# M251_v1 register map
File version: 1.0
Registers are 32-bit, read-write, reset 0x0 unless marked. A register's access mark holds for its fields unless they carry their own. Offsets are from the block's base; [hi:lo] are bit positions; {n}, {i} and the like mark numbered series; 'fields as' and 'values as' point back to an identical list.

## SYS — SYS Register Map
Base 0x40000000
0x00 SYS_PDID ro reset not defined — Part Device Identification Number Register
  [31:0] PDID — Part Device Identification Number (Read Only). This register reflects device part number code. Software can read this register to identify which device is used.
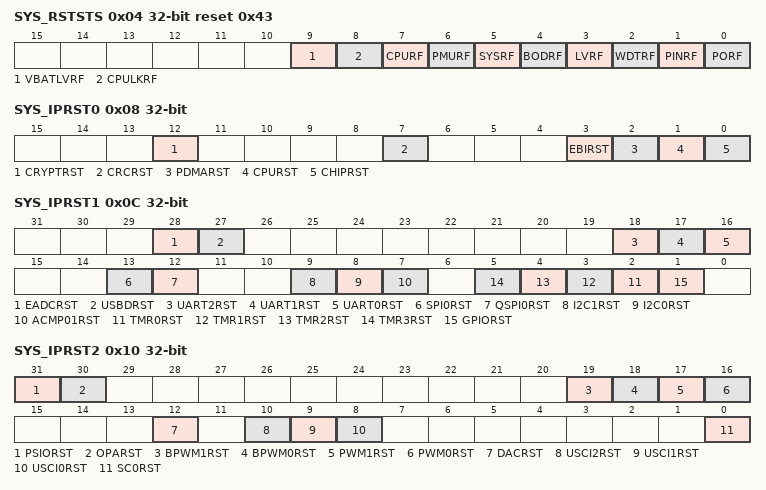
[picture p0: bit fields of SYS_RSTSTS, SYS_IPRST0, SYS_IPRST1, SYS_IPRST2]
0x04 SYS_RSTSTS reset 0x43 — System Reset Status Register
  [9] VBATLVRF — VBAT LVR Reset Flag. The VBAT LVR reset flag is set by the 'Reset Signal' from the VBAT Low Voltage Reset Controller to indicate the previous reset source. Note: Write 1 to clear this bit to 0.
    0=No reset from VBAT LVR; 1=VBAT LVR controller had issued the reset signal to reset the system
  [8] CPULKRF — CPU Lockup Reset Flag. Note: Write 1 to clear this bit to 0. Note2: When CPU lockup happened under ICE is connected, This flag will set to 1 but chip will not reset.
    0=No reset from CPU lockup happened; 1=The Cortex-M23lockup happened and chip is reset
  [7] CPURF — CPU Reset Flag. The CPU reset flag is set by hardware if software writes CPURST (SYS_IPRST0[1]) 1 to reset Cortex- M23Core and Flash Memory Controller (FMC). Note: Write 1 to clear this bit to 0.
    0=No reset from CPU; 1=The Cortex-M23 Core and FMC are reset by software setting CPURST to 1
  [6] PMURF — PMU Reset Flag, The PMU reset flag is set by any reset signal when MCU is in power down state. Note: Write 1 to clear this bit to 0.
    0=No reset in power down state; 1=Any reset signal happens in power down state
  [5] SYSRF — System Reset Flag. The system reset flag is set by the 'Reset Signal' from the CortexM23Core to indicate the previous reset source. Note: Write 1 to clear this bit to 0.
    0=No reset from Cortex-M23; 1=The Cortex- M23 had issued the reset signal to reset the system by writing 1 to the bit SYSRESETREQ(AIRCR[2], Application Interrupt and Reset Control Register, address = 0xE000ED0C) in system control registers of Cortex-M23core
  [4] BODRF — BOD Reset Flag. The BOD reset flag is set by the 'Reset Signal' from the Brown-Out Detector to indicate the previous reset source. Note: Write 1 to clear this bit to 0.
    0=No reset from BOD; 1=The BOD had issued the reset signal to reset the system
  [3] LVRF — LVR Reset Flag. The LVR reset flag is set by the 'Reset Signal' from the Low Voltage Reset Controller to indicate the previous reset source. Note: Write 1 to clear this bit to 0.
    0=No reset from LVR; 1=LVR controller had issued the reset signal to reset the system
  [2] WDTRF — WDT Reset Flag. The WDT reset flag is set by the 'Reset Signal' from the Watchdog Timer or Window Watchdog Timer to indicate the previous reset source. Note1: Write 1 to clear this bit to 0. Note2: Watchdog Timer register RSTF(WDT_CTL[2]) bit is set if the system has been reset by WDT time-out reset. Window Watchdog Timer register WWDTRF(WWDT_STATUS[1]) bit is set if the system has been reset by WWDT time-out reset.
    0=No reset from watchdog timer or window watchdog timer; 1=The watchdog timer or window watchdog timer had issued the reset signal to reset the system
  [1] PINRF — NRESET Pin Reset Flag. The nRESET pin reset flag is set by the 'Reset Signal' from the nRESET Pin to indicate the previous reset source. Note: Write 1 to clear this bit to 0.
    0=No reset from nRESET pin; 1=Pin nRESET had issued the reset signal to reset the system
  [0] PORF — POR Reset Flag. The POR reset flag is set by the 'Reset Signal' from the Power-on Reset (POR) Controller or bit CHIPRST (SYS_IPRST0[0]) to indicate the previous reset source. Note: Write 1 to clear this bit to 0.
    0=No reset from POR or CHIPRST; 1=Power-on Reset (POR) or CHIPRST had issued the reset signal to reset the system
0x08 SYS_IPRST0 — Peripheral Reset Control Register 0
  [12] CRYPTRST — CRYPTO Controller Reset (Write Protect). Setting this bit to 1 will generate a reset signal to the CRYPTO controller. User needs to set this bit to 0 to release from the reset state. Note: This bit is write protected. Refer to the SYS_REGLCTL register.
    0=CRYPTO controller normal operation; 1=CRYPTO controller reset
  [7] CRCRST — CRC Calculation Controller Reset (Write Protect). Setting this bit to 1 will generate a reset signal to the CRC calculation controller. User needs to set this bit to 0 to release from the reset state. Note: This bit is write protected. Refer to the SYS_REGLCTL register.
    0=CRC calculation controller normal operation; 1=CRC calculation controller reset
  [3] EBIRST — EBI Controller Reset (Write Protect). Setting this bit to 1 will generate a reset signal to the EBI. User needs to set this bit to 0 to release from the reset state. Note: This bit is write protected. Refer to the SYS_REGLCTL register.
    0=EBI controller normal operation; 1=EBI controller reset
  [2] PDMARST — PDMA Controller Reset (Write Protect). Setting this bit to 1 will generate a reset signal to the PDMA. User needs to set this bit to 0 to release from reset state. Note: This bit is write protected. Refer to the SYS_REGLCTL register.
    0=PDMA controller normal operation; 1=PDMA controller reset
  [1] CPURST — Processor Core One-shot Reset (Write Protect). Setting this bit will only reset the processor core and Flash Memory Controller(FMC), and this bit will automatically return to 0 after the 2 clock cycles. Note: This bit is write protected. Refer to the SYS_REGLCTL register.
    0=Processor core normal operation; 1=Processor core one-shot reset
  [0] CHIPRST — Chip One-shot Reset (Write Protect). Setting this bit will reset the whole chip, including Processor core and all peripherals, and this bit will automatically return to 0 after the 2 clock cycles. The CHIPRST is same as the POR reset, all the chip controllers is reset and the chip setting from Flash are also reload. For the difference between CHIPRST and SYSRESETREQ(AIRCR[2]), please refer to section 6.2.2. Note1: This bit is write protected. Refer to the SYS_REGLCTL register. Note2: Reset by power on reset
    0=Chip normal operation; 1=Chip one-shot reset
0x0C SYS_IPRST1 — Peripheral Reset Control Register 1
  [28] EADCRST — EADC Controller Reset
    0=EADC controller normal operation; 1=EADC controller reset
  [27] USBDRST — USBD Controller Reset
    0=USBD controller normal operation; 1=USBD controller reset
  [18] UART2RST — UART2 Controller Reset
    0=UART2 controller normal operation; 1=UART2 controller reset
  [17] UART1RST — UART1 Controller Reset
    0=UART1 controller normal operation; 1=UART1 controller reset
  [16] UART0RST — UART0 Controller Reset
    0=UART0 controller normal operation; 1=UART0 controller reset
  [13] SPI0RST — SPI0 Controller Reset
    0=SPI0 controller normal operation; 1=SPI0 controller reset
  [12] QSPI0RST — QSPI0 Controller Reset
    0=QSPI0 controller normal operation; 1=QSPI0 controller reset
  [9] I2C1RST — I2C1 Controller Reset
    0=I2C1 controller normal operation; 1=I2C1 controller reset
  [8] I2C0RST — I2C0 Controller Reset
    0=I2C0 controller normal operation; 1=I2C0 controller reset
  [7] ACMP01RST — Analog Comparator 0/1 Controller Reset
    0=Analog Comparator 0/1 controller normal operation; 1=Analog Comparator 0/1 controller reset
  [n+2] TMR{n}RST (n=0..3) — Timer{n} Controller Reset
    0=Timer{n} controller normal operation; 1=Timer{n} controller reset
  [1] GPIORST — GPIO Controller Reset
    0=GPIO controller normal operation; 1=GPIO controller reset
0x10 SYS_IPRST2 — Peripheral Reset Control Register 2
  [31] PSIORST
  [30] OPARST — OP Amplifier (OPA) Controller Reset
    0=OPA controller normal operation; 1=OPA controller reset
  [19] BPWM1RST — BPWM1 Controller Reset
    0=BPWM1 controller normal operation; 1=BPWM1 controller reset
  [18] BPWM0RST — BPWM0 Controller Reset
    0=BPWM0 controller normal operation; 1=BPWM0 controller reset
  [17] PWM1RST — PWM1 Controller Reset
    0=PWM1 controller normal operation; 1=PWM1 controller reset
  [16] PWM0RST — PWM0 Controller Reset
    0=PWM0 controller normal operation; 1=PWM0 controller reset
  [12] DACRST — DAC Controller Reset
    0=DAC controller normal operation; 1=DAC controller reset
  [10] USCI2RST — USCI2 Controller Reset
    0=USCI2 controller normal operation; 1=USCI2 controller reset
  [9] USCI1RST — USCI1 Controller Reset
    0=USCI1 controller normal operation; 1=USCI1 controller reset
  [8] USCI0RST — USCI0 Controller Reset
    0=USCI0 controller normal operation; 1=USCI0 controller reset
  [0] SC0RST — SC0 Controller Reset
    0=SC0 controller normal operation; 1=SC0 controller reset
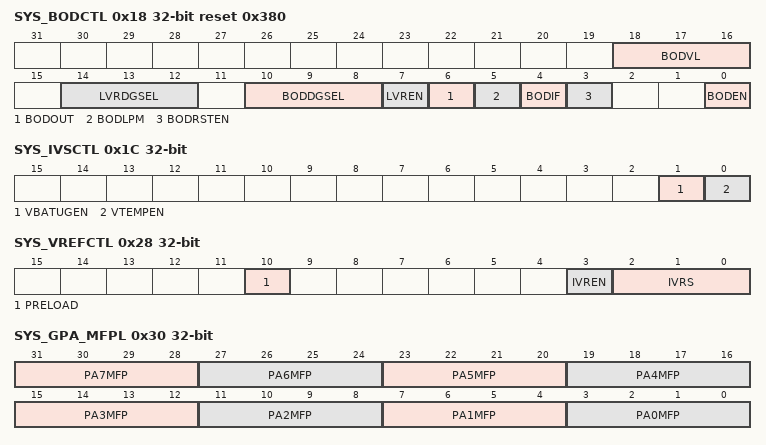
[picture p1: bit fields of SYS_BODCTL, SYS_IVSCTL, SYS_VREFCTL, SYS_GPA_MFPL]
0x18 SYS_BODCTL reset 0x380 (reset mask 0xFFF0FFF0) — Brown-out Detector Control Register
  [18:16] BODVL — Brown-out Detector Threshold Voltage Selection (Write Protect). The default value is set by Flash controller user configuration register CBOV (CONFIG0 [23:21]). Note: This bit is write protected. Refer to the SYS_REGLCTL register. Note: Reset by power on reset.
    1=Brown-Out Detector threshold voltage is 1.8V; 2=Brown-Out Detector threshold voltage is 2.0V; 3=Brown-Out Detector threshold voltage is 2.4V; 4=Brown-Out Detector threshold voltage is 2.7V; 5=Brown-Out Detector threshold voltage is 3.0V; 6=Brown-Out Detector threshold voltage is 3.7V; 7=Brown-Out Detector threshold voltage is 4.4V
  [14:12] LVRDGSEL — LVR Output De-glitch Time Select (Write Protect). Note: These bits are write protected. Refer to the SYS_REGLCTL register. Note: The MIRC enabled automatically when LVRDGSEL is not 000 and LVREN is 1.
    0=Without de-glitch function; 1=4 MIRC clock (4 MHz), 1 us; 2=8 MIRC clock (4 MHz), 2 us; 3=16 MIRC clock (4 MHz), 4 us; 4=32 MIRC clock (4 MHz), 8 us; 5=64 MIRC clock (4 MHz), 16 us; 6=128 MIRC clock (4 MHz), 32 us; 7=256 MIRC clock (4 MHz), 64 us
  [10:8] BODDGSEL — Brown-out Detector Output De-glitch Time Select (Write Protect). Note: These bits are write protected. Refer to the SYS_REGLCTL register.
    0=BOD output is sampled by LIRC; 1=4 system clock (HCLK); 2=8 system clock (HCLK); 3=16 system clock (HCLK); 4=32 system clock (HCLK); 5=64 system clock (HCLK); 6=128 system clock (HCLK); 7=256 system clock (HCLK)
  [7] LVREN — Low Voltage Reset Enable Bit (Write Protect). The LVR function resets the chip when the input power voltage is lower than LVR circuit setting. LVR function is enabled by default. Note1: After enabling the bit, the LVR function will be active with 3ms delay for LVR output stable (default). Note2: For BOD low power mode to be active, this bit must be set 1. Note3: This bit is write protected. Refer to the SYS_REGLCTL register.
    0=Low Voltage Reset function Disabled; 1=Low Voltage Reset function Enabled
  [6] BODOUT — Brown-out Detector Output Status. It means the detected voltage is lower than BODVL setting. If the BODEN is 0, BOD function disabled, this bit always responds 0000.
    0=Brown-out Detector output status is 0; 1=Brown-out Detector output status is 1
  [5] BODLPM — Brown-out Detector Low Power Mode (Write Protect). Note1: The BOD consumes about 100uA in normal mode, the low power mode can reduce the current to about 1/10 but slow the BOD response. Note2: For BOD low power mode to be active, LVREN must be set to 1. Note3: This bit is write protected. Refer to the SYS_REGLCTL register.
    0=BOD operate in normal mode (default); 1=BOD Low Power mode Enabled
  [4] BODIF — Brown-out Detector Interrupt Flag. Note: Write 1 to clear this bit to 0.
    0=Brown-out Detector does not detect any voltage draft at VDD down through or up through the voltage of BODVL setting; 1=When Brown-out Detector detects the VDD is dropped down through the voltage of BODVL setting or the VDD is raised up through the voltage of BODVL setting, this bit is set to 1 and the brown-out interrupt is requested if brown-out interrupt is enabled
  [3] BODRSTEN — Brown-out Reset Enable Bit (Write Protect). The default value is set by Flash controller user configuration register CBORST(CONFIG0[20]) bit. Note1: While the Brown-out Detector function is enabled (BODEN high) and BOD reset function is enabled (BODRSTEN high), BOD will assert a signal to reset chip when the detected voltage is lower than the threshold (BODOUT high). While the BOD function is enabled (BODEN high) and BOD interrupt function is enabled (BODRSTEN low), BOD will assert an interrupt if BODOUT is high. BOD interrupt will keep till to the BODEN set to 0. BOD interrupt can be blocked by disabling the NVIC BOD interrupt or disabling BOD function (set BODEN low). Note2: This bit is write protected. Refer to the SYS_REGLCTL register. Note3: Reset by power on reset.
    0=Brown-out 'INTERRUPT' function Enabled; 1=Brown-out 'RESET' function Enabled
  [0] BODEN — Brown-out Detector Enable Bit (Write Protect). The default value is set by Flash controller user configuration register CBODEN (CONFIG0 [19]). Note1: This bit is write protected. Refer to the SYS_REGLCTL register. Note2: Reset by power on reset.
    0=Brown-out Detector function Disabled; 1=Brown-out Detector function Enabled
0x1C SYS_IVSCTL — Internal Voltage Source Control Register
  [1] VBATUGEN — VBAT Unity Gain Buffer Enable Bit. This bit is used to enable/disable VBAT unity gain buffer function. Note: After this bit is set to 1, the value of VBAT unity gain buffer output voltage can be obtained from ADC conversion result
    0=VBAT unity gain buffer function Disabled (default); 1=VBAT unity gain buffer function Enabled
  [0] VTEMPEN — Temperature Sensor Enable Bit. This bit is used to enable/disable temperature sensor function. .
    0=Temperature sensor function Disabled (default); 1=Temperature sensor function Enabled
0x24 SYS_PORCTL0 — Power-On-reset Controller Register 0
  [15:0] PORMASK — Power-on Reset Mask Enable Bit (Write Protect). When powered on, the POR circuit generates a reset signal to reset the whole chip function, but noise on the power may cause the POR active again. User can mask internal POR signal to avoid unpredictable noise to cause chip reset by writing 0x5AA5 to this field. The POR function will be active again when this field is set to another value or chip is reset by other reset source, including: nRESET, Watchdog, LVR reset, BOD reset, ICE reset command and the software-chip reset function. Note: These bits are write protected. Refer to the SYS_REGLCTL register.
0x28 SYS_VREFCTL — VREF Control Register
  [10] PRELOAD — Preload Enable Bit. Note: This bit is used to speed up charging external capacitor of VREF.If INT_VREF voltage is stable, this bit has to be disabled.
    0=Preload Disabled (default); 1=Preload Enabled
  [3] IVREN — Internal Voltage Reference Module Enable Bit (Write Protect)
    0=Internal voltage reference module Disabled; 1=Internal voltage reference module Enabled
  [2:0] IVRS — Internal Voltage Reference Scale (Write Protect)
    0=Internal voltage reference(INT_VREF) set to 1.536V; 1=Internal voltage reference(INT_VREF) set to 2.048V; 2=Internal voltage reference(INT_VREF) set to 2.56V; 3=Internal voltage reference(INT_VREF) set to 3.072V; 4=Internal voltage reference(INT_VREF) set to 4.096V
0x30 SYS_GPA_MFPL — GPIOA Low Byte Multiple Function Control Register
  [31:28] PA7MFP — PA.7 Multi-function Pin Selection
  [27:24] PA6MFP — PA.6 Multi-function Pin Selection
  [23:20] PA5MFP — PA.5 Multi-function Pin Selection
  [19:16] PA4MFP — PA.4 Multi-function Pin Selection
  [15:12] PA3MFP — PA.3 Multi-function Pin Selection
  [11:8] PA2MFP — PA.2 Multi-function Pin Selection
  [7:4] PA1MFP — PA.1 Multi-function Pin Selection
  [3:0] PA0MFP — PA.0 Multi-function Pin Selection
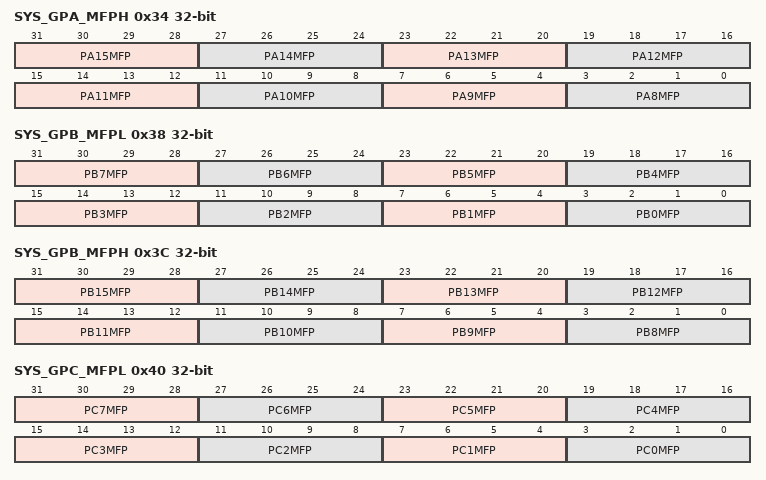
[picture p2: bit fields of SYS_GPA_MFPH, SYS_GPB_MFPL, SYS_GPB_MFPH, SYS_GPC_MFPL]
0x34 SYS_GPA_MFPH — GPIOA High Byte Multiple Function Control Register
  [31:28] PA15MFP — PA.15 Multi-function Pin Selection
  [27:24] PA14MFP — PA.14 Multi-function Pin Selection
  [23:20] PA13MFP — PA.13 Multi-function Pin Selection
  [19:16] PA12MFP — PA.12 Multi-function Pin Selection
  [15:12] PA11MFP — PA.11 Multi-function Pin Selection
  [11:8] PA10MFP — PA.10 Multi-function Pin Selection
  [7:4] PA9MFP — PA.9 Multi-function Pin Selection
  [3:0] PA8MFP — PA.8 Multi-function Pin Selection
0x38 SYS_GPB_MFPL — GPIOB Low Byte Multiple Function Control Register
  [31:28] PB7MFP — PB.7 Multi-function Pin Selection
  [27:24] PB6MFP — PB.6 Multi-function Pin Selection
  [23:20] PB5MFP — PB.5 Multi-function Pin Selection
  [19:16] PB4MFP — PB.4 Multi-function Pin Selection
  [15:12] PB3MFP — PB.3 Multi-function Pin Selection
  [11:8] PB2MFP — PB.2 Multi-function Pin Selection
  [7:4] PB1MFP — PB.1 Multi-function Pin Selection
  [3:0] PB0MFP — PB.0 Multi-function Pin Selection
0x3C SYS_GPB_MFPH — GPIOB High Byte Multiple Function Control Register
  [31:28] PB15MFP — PB.15 Multi-function Pin Selection
  [27:24] PB14MFP — PB.14 Multi-function Pin Selection
  [23:20] PB13MFP — PB.13 Multi-function Pin Selection
  [19:16] PB12MFP — PB.12 Multi-function Pin Selection
  [15:12] PB11MFP — PB.11 Multi-function Pin Selection
  [11:8] PB10MFP — PB.10 Multi-function Pin Selection
  [7:4] PB9MFP — PB.9 Multi-function Pin Selection
  [3:0] PB8MFP — PB.8 Multi-function Pin Selection
0x40 SYS_GPC_MFPL — GPIOC Low Byte Multiple Function Control Register
  [31:28] PC7MFP — PC.7 Multi-function Pin Selection
  [27:24] PC6MFP — PC.6 Multi-function Pin Selection
  [23:20] PC5MFP — PC.5 Multi-function Pin Selection
  [19:16] PC4MFP — PC.4 Multi-function Pin Selection
  [15:12] PC3MFP — PC.3 Multi-function Pin Selection
  [11:8] PC2MFP — PC.2 Multi-function Pin Selection
  [7:4] PC1MFP — PC.1 Multi-function Pin Selection
  [3:0] PC0MFP — PC.0 Multi-function Pin Selection
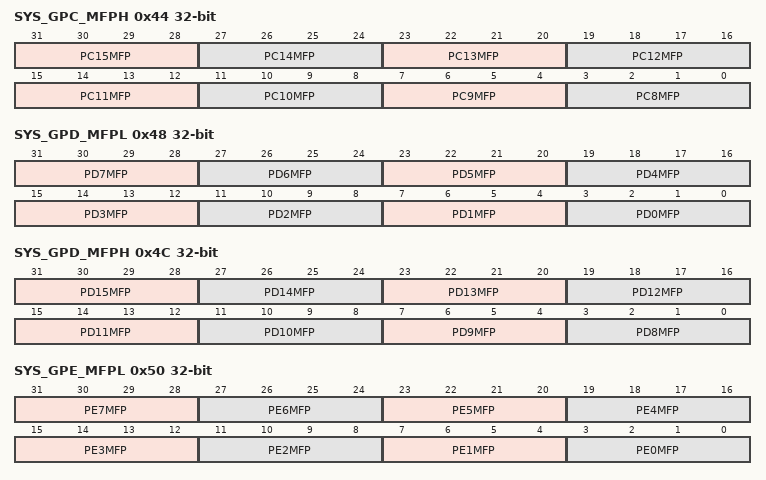
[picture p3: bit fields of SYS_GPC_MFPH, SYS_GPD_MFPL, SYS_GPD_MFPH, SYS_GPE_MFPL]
0x44 SYS_GPC_MFPH — GPIOC High Byte Multiple Function Control Register
  [31:28] PC15MFP — PC.15 Multi-function Pin Selection
  [27:24] PC14MFP — PC.14 Multi-function Pin Selection
  [23:20] PC13MFP — PC.13 Multi-function Pin Selection
  [19:16] PC12MFP — PC.12 Multi-function Pin Selection
  [15:12] PC11MFP — PC.11 Multi-function Pin Selection
  [11:8] PC10MFP — PC.10 Multi-function Pin Selection
  [7:4] PC9MFP — PC.9 Multi-function Pin Selection
  [3:0] PC8MFP — PC.8 Multi-function Pin Selection
0x48 SYS_GPD_MFPL — GPIOD Low Byte Multiple Function Control Register
  [31:28] PD7MFP — PD.7 Multi-function Pin Selection
  [27:24] PD6MFP — PD.6 Multi-function Pin Selection
  [23:20] PD5MFP — PD.5 Multi-function Pin Selection
  [19:16] PD4MFP — PD.4 Multi-function Pin Selection
  [15:12] PD3MFP — PD.3 Multi-function Pin Selection
  [11:8] PD2MFP — PD.2 Multi-function Pin Selection
  [7:4] PD1MFP — PD.1 Multi-function Pin Selection
  [3:0] PD0MFP — PD.0 Multi-function Pin Selection
0x4C SYS_GPD_MFPH — GPIOD High Byte Multiple Function Control Register
  [31:28] PD15MFP — PD.15 Multi-function Pin Selection
  [27:24] PD14MFP — PD.14 Multi-function Pin Selection
  [23:20] PD13MFP — PD.13 Multi-function Pin Selection
  [19:16] PD12MFP — PD.12 Multi-function Pin Selection
  [15:12] PD11MFP — PD.11 Multi-function Pin Selection
  [11:8] PD10MFP — PD.10 Multi-function Pin Selection
  [7:4] PD9MFP — PD.9 Multi-function Pin Selection
  [3:0] PD8MFP — PD.8 Multi-function Pin Selection
0x50 SYS_GPE_MFPL — GPIOE Low Byte Multiple Function Control Register
  [31:28] PE7MFP — PE.7 Multi-function Pin Selection
  [27:24] PE6MFP — PE.6 Multi-function Pin Selection
  [23:20] PE5MFP — PE.5 Multi-function Pin Selection
  [19:16] PE4MFP — PE.4 Multi-function Pin Selection
  [15:12] PE3MFP — PE.3 Multi-function Pin Selection
  [11:8] PE2MFP — PE.2 Multi-function Pin Selection
  [7:4] PE1MFP — PE.1 Multi-function Pin Selection
  [3:0] PE0MFP — PE.0 Multi-function Pin Selection
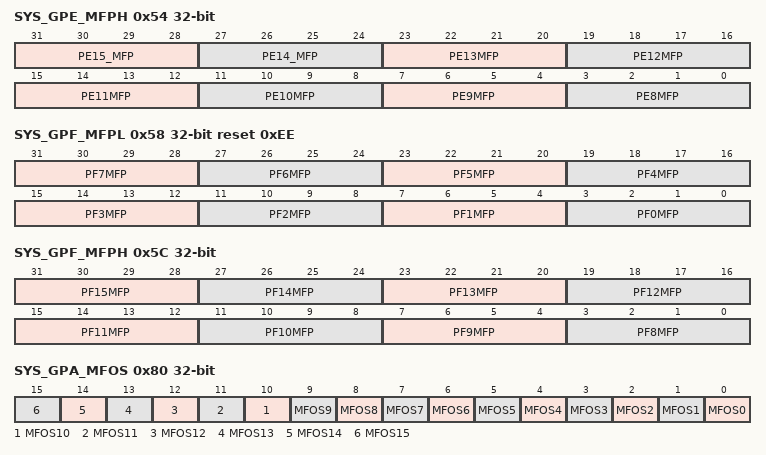
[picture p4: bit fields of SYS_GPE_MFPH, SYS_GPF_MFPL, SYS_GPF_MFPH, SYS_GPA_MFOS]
0x54 SYS_GPE_MFPH — GPIOE High Byte Multiple Function Control Register
  [31:28] PE15_MFP — PE.15 Multi-function Pin Selection
  [27:24] PE14_MFP — PE.14 Multi-function Pin Selection
  [23:20] PE13MFP — PE.13 Multi-function Pin Selection
  [19:16] PE12MFP — PE.12 Multi-function Pin Selection
  [15:12] PE11MFP — PE.11 Multi-function Pin Selection
  [11:8] PE10MFP — PE.10 Multi-function Pin Selection
  [7:4] PE9MFP — PE.9 Multi-function Pin Selection
  [3:0] PE8MFP — PE.8 Multi-function Pin Selection
0x58 SYS_GPF_MFPL reset 0xEE — GPIOF Low Byte Multiple Function Control Register
  [31:28] PF7MFP — PF.7 Multi-function Pin Selection
  [27:24] PF6MFP — PF.6 Multi-function Pin Selection
  [23:20] PF5MFP — PF.5 Multi-function Pin Selection
  [19:16] PF4MFP — PF.4 Multi-function Pin Selection
  [15:12] PF3MFP — PF.3 Multi-function Pin Selection
  [11:8] PF2MFP — PF.2 Multi-function Pin Selection
  [7:4] PF1MFP — PF.1 Multi-function Pin Selection
  [3:0] PF0MFP — PF.0 Multi-function Pin Selection
0x5C SYS_GPF_MFPH — GPIOF High Byte Multiple Function Control Register
  [31:28] PF15MFP — PF.15 Multi-function Pin Selection
  [27:24] PF14MFP — PF.14 Multi-function Pin Selection
  [23:20] PF13MFP — PF.13 Multi-function Pin Selection
  [19:16] PF12MFP — PF.12 Multi-function Pin Selection
  [15:12] PF11MFP — PF.11 Multi-function Pin Selection
  [11:8] PF10MFP — PF.10 Multi-function Pin Selection
  [7:4] PF9MFP — PF.9 Multi-function Pin Selection
  [3:0] PF8MFP — PF.8 Multi-function Pin Selection
0x80 SYS_GPA_MFOS — GPIOA Multiple Function Output Select Register
  [all] fields
    0=Multiple funtion pin output mode type is Push-pull mode; 1=Multiple funtion pin output mode type is Open-drain mode
  [n] MFOS{n} (n=0..15) — GPIOA-f Pin[n] Multiple Function Pin Output Mode Select. This bit used to select multiple function pin output mode type for Px.n pin
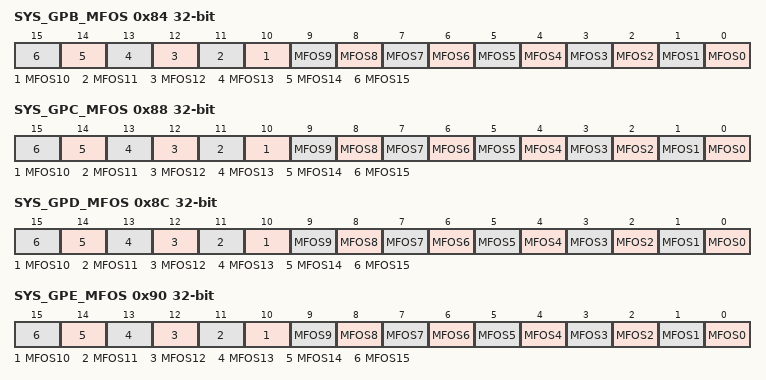
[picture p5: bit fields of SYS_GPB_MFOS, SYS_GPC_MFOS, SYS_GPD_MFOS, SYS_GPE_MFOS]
0x84 SYS_GPB_MFOS — GPIOB Multiple Function Output Select Register
  fields as SYS_GPA_MFOS
0x88 SYS_GPC_MFOS — GPIOC Multiple Function Output Select Register
  fields as SYS_GPA_MFOS
0x8C SYS_GPD_MFOS — GPIOD Multiple Function Output Select Register
  fields as SYS_GPA_MFOS
0x90 SYS_GPE_MFOS — GPIOE Multiple Function Output Select Register
  fields as SYS_GPA_MFOS
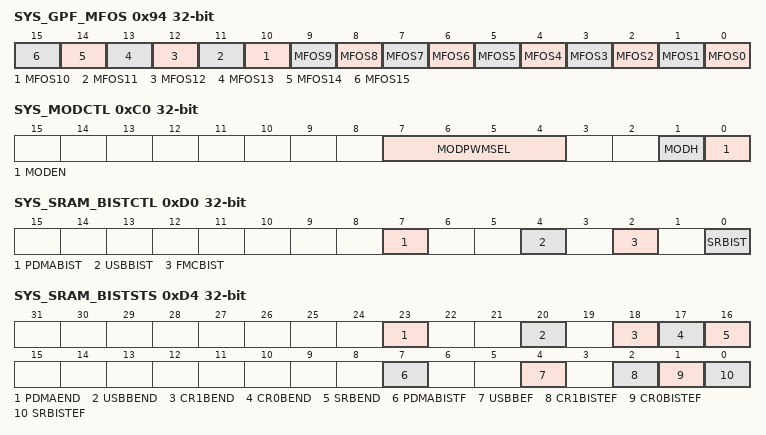
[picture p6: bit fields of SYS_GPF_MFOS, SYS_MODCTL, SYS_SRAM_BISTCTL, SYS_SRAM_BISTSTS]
0x94 SYS_GPF_MFOS — GPIOF Multiple Function Output Select Register
  fields as SYS_GPA_MFOS
0xC0 SYS_MODCTL — Modulation Control Register
  [7:4] MODPWMSEL — PWM0 Channel Select for Modulation. Select the PWM0 channel to modulate with the UART0_TXD or USCI0_DAT1. 0000: PWM0 Channel 0 modulate with UART0_TXD. 0001: PWM0 Channel 1 modulate with UART0_TXD. 0010: PWM0 Channel 2 modulate with UART0_TXD. 0011: PWM0 Channel 3 modulete with UART0_TXD. 0100: PWM0 Channel 4 modulete with UART0_TXD. 0101: PWM0 Channel 5 modulete with UART0_TXD. 0110: Reserved. 0111: Reserved. 1000: PWM0 Channel 0 modulate with USCI0_DAT1. 1001: PWM0 Channel 1 modulate with USCI0_DAT1. 1010: PWM0 Channel 2 modulate with USCI0_DAT1. 1011: PWM0 Channel 3 modulete with USCI0_DAT1. 1100: PWM0 Channel 4 modulete with USCI0_DAT1. 1101: PWM0 Channel 5 modulete with USCI0_DAT1. 1110: Reserved. 1111: Reserved. Note: This bis is valid while MODEN (SYS_MODCTL[0]) is set to 1.
  [1] MODH — Modulation at Data High. Select modulation pulse(PWM0) at high or low of UART0_TXD or USCI0_DAT1
    0=Modulation pulse at UART0_TXD low or USCI0_DAT1 low; 1=Modulation pulse at UART0_TXD high or USCI0_DAT1 high
  [0] MODEN — Modulation Function Enable Bit. This bit enables modulation funcion by modulating with PWM0 channel output and USCI0(USCI0_DAT1) or UART0(UART0_TXD) output.
    0=Modulation Function Disabled; 1=Modulation Function Enabled
0xD0 SYS_SRAM_BISTCTL — System SRAM BIST Test Control Register
  [7] PDMABIST — PDMA BIST Enable Bit (Write Protect). This bit enables BIST test for PDMA RAM. Note: This bit is write protected. Refer to the SYS_REGLCTL register.
    0=System PDMA BIST Disabled; 1=Sstem PDMA BIST Enabled
  [4] USBBIST — USB BIST Enable Bit (Write Protect). This bit enables BIST test for USB RAM. Note: This bit is write protected. Refer to the SYS_REGLCTL register.
    0=System USB BIST Disabled; 1=System USB BIST Enabled
  [2] FMCBIST — FMC CACHE BIST Enable Bit (Write Protect). This bit enables BIST test for CACHE RAM. Note: This bit is write protected. Refer to the SYS_REGLCTL register.
    0=System CACHE BIST Disabled; 1=System CACHE BIST Enabled
  [0] SRBIST — SRAM BIST Enable Bit (Write Protect). This bit enables BIST test for SRAM. Note: This bit is write protected. Refer to the SYS_REGLCTL register.
    0=System SRAM BIST Disabled; 1=System SRAM BIST Enabled
0xD4 SYS_SRAM_BISTSTS ro (reset mask 0xFF00FF00) — System SRAM BIST Test Status Register
  [23] PDMAEND — PDMA SRAM BIST Test Finish
    0=PDMA SRAM BIST is active; 1=PDMA SRAM BIST test finished
  [20] USBBEND — USB SRAM BIST Test Finish
    0=USB SRAM BIST is active; 1=USB SRAM BIST test finished
  [18] CR1BEND — CACHE 1 SRAM BIST Test Finish
    0=System CACHE RAM BIST is active; 1=System CACHE RAM BIST test finished
  [17] CR0BEND — CACHE 0 SRAM BIST Test Finish
    values as CR1BEND
  [16] SRBEND — SRAM BIST Test Finish
    0=System SRAM BIST active; 1=system SRAM BIST finished
  [7] PDMABISTF — PDMA SRAM BIST Failed Flag
    0=PDMA SRAM BIST pass; 1=PDMA SRAM BIST failed
  [4] USBBEF — USB SRAM BIST Fail Flag
    0=USB SRAM BIST test pass; 1=USB SRAM BIST test failed
  [2] CR1BISTEF — CACHE1 SRAM BIST Fail Flag
    0=System CACHE RAM BIST test pass; 1=System CACHE RAM BIST test failed
  [1] CR0BISTEF — CACHE0 SRAM BIST Fail Flag
    values as CR1BISTEF
  [0] SRBISTEF — System SRAM BIST Fail Flag
    0=System SRAM BIST test pass; 1=System SRAM BIST test failed
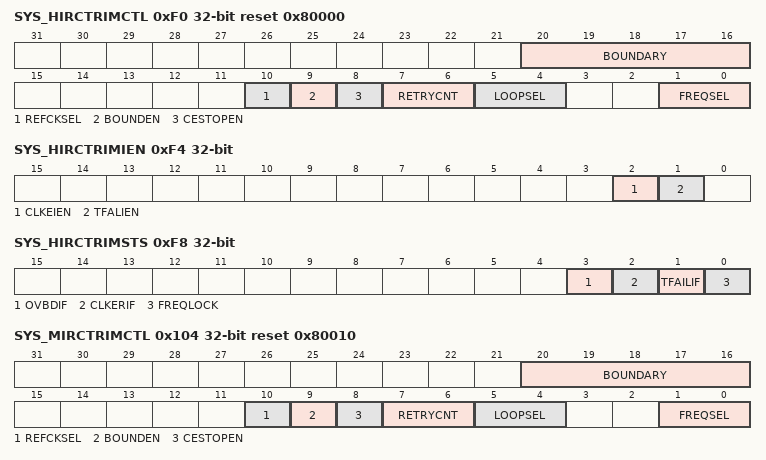
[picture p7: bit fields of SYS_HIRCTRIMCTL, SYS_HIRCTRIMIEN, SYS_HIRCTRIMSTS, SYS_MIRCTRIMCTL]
0xF0 SYS_HIRCTRIMCTL reset 0x80000 — HIRC Trim Control Register
  [20:16] BOUNDARY — Boundary Selection. Fill the boundary range from 0x1 to 0x1F, 0x0 is reserved. Note: This field is effective only when the BOUNDEN(SYS_HIRCTRIMCTL[9]) is enable.
  [10] REFCKSEL — Reference Clock Selection
    0=HIRC trim reference clock is from LXT (32.768 kHz); 1=HIRC trim reference clock is from internal USB synchronous mode
  [9] BOUNDEN — Boundary Enable Bit
    0=Boundary function Disabled; 1=Boundary function Enabled
  [8] CESTOPEN — Clock Error Stop Enable Bit
    0=The trim operation keeps going if clock is inaccurate; 1=The trim operation stops if clock is inaccurate
  [7:6] RETRYCNT — Trim Value Update Limitation Count. This field defines that how many times the auto trim circuit will try to update the HIRC trim value before the frequency of HIRC locked. Once the HIRC locked, the internal trim value update counter will be reset. If the trim value update counter reached this limitation value and frequency of HIRC still doesn't lock, the auto trim operation will be disabled and FREQSEL will be cleared to 00.
    0=Trim retry count limitation is 64 loops; 1=Trim retry count limitation is 128 loops; 2=Trim retry count limitation is 256 loops; 3=Trim retry count limitation is 512 loops
  [5:4] LOOPSEL — Trim Calculation Loop Selection. This field defines that trim value calculation is based on how many reference clocks. Note: For example, if LOOPSEL is set as 00, auto trim circuit will calculate trim value based on the average frequency difference in 4 clocks of reference clock.
    0=Trim value calculation is based on average difference in 4 clocks of reference clock; 1=Trim value calculation is based on average difference in 8 clocks of reference clock; 2=Trim value calculation is based on average difference in 16 clocks of reference clock; 3=Trim value calculation is based on average difference in 32 clocks of reference clock
  [1:0] FREQSEL — Trim Frequency Selection. This field indicates the target frequency of 48 MHz internal high speed RC oscillator (HIRC) auto trim. During auto trim operation, if clock error detected with CESTOPEN is set to 1 or trim retry limitation count reached, this field will be cleared to 00 automatically.
    0=Disable HIRC auto trim function; 1=Enable HIRC auto trim function and trim HIRC to 48 MHz
0xF4 SYS_HIRCTRIMIEN — HIRC Trim Interrupt Enable Register
  [2] CLKEIEN — Clock Error Interrupt Enable Bit. This bit controls if CPU would get an interrupt while clock is inaccuracy during auto trim operation. If this bit is set to1, and CLKERRIF(SYS_HIRCTRIMSTS[2]) is set during auto trim operation, an interrupt will be triggered to notify the clock frequency is inaccuracy.
    0=Disable CLKERRIF(SYS_HIRCTRIMSTS[2]) status to trigger an interrupt to CPU; 1=Enable CLKERRIF(SYS_HIRCTRIMSTS[2]) status to trigger an interrupt to CPU
  [1] TFALIEN — Trim Failure Interrupt Enable Bit. This bit controls if an interrupt will be triggered while HIRC trim value update limitation count reached and HIRC frequency still not locked on target frequency set by FREQSEL(SYS_HIRCTRIMCTL[1:0]). If this bit is high and TFAILIF(SYS_HIRCTRIMSTS[1]) is set during auto trim operation, an interrupt will be triggered to notify that HIRC trim value update limitation count was reached.
    0=Disable TFAILIF(SYS_HIRCTRIMSTS[1]) status to trigger an interrupt to CPU; 1=Enable TFAILIF(SYS_HIRCTRIMSTS[1]) status to trigger an interrupt to CPU
0xF8 SYS_HIRCTRIMSTS — HIRC Trim Interrupt Status Register
  [3] OVBDIF — Over Boundary Status. When the over boundary function is set, if there occurs the over boundary condition, this flag will be set. Note: Write 1 to clear this flag.
    0=Over boundary coundition did not occur; 1=Over boundary coundition occurred
  [2] CLKERIF — Clock Error Interrupt Status. When the frequency of 32.768 kHz external low speed crystal oscillator (LXT) or 48 MHz internal high speed RC oscillator (HIRC) is shift larger to unreasonable value, this bit will be set and to be an indicate that clock frequency is inaccuracy. Once this bit is set to 1, the auto trim operation stopped and FREQSEL(SYS_HIRCTRIMCTL[1:0]) will be cleared to 00 by hardware automatically if CESTOPEN(SYS_HIRCTRIMCTL[8]) is set to 1. If this bit is set and CLKEIEN(SYS_HIRCTRIMIEN[2]) is high, an interrupt will be triggered to notify the clock frequency is inaccuracy. Write 1 to clear this to 0. Note: Reset by power on reset.
    0=Clock frequency is accuracy; 1=Clock frequency is inaccuracy
  [1] TFAILIF — Trim Failure Interrupt Status. This bit indicates that HIRC trim value update limitation count reached and the HIRC clock frequency still doesn't be locked. Once this bit is set, the auto trim operation stopped and FREQSEL(SYS_HIRCTRIMCTL[1:0]) will be cleared to 00 by hardware automatically. If this bit is set and TFAILIEN(SYS_HIRCTRIMIEN[1]) is high, an interrupt will be triggered to notify that HIRC trim value update limitation count was reached. Write 1 to clear this to 0. Note: Reset by power on reset.
    0=Trim value update limitation count does not reach; 1=Trim value update limitation count reached and HIRC frequency still not locked
  [0] FREQLOCK — HIRC Frequency Lock Status. This bit indicates the HIRC frequency is locked. This is a status bit and doesn't trigger any interrupt. Write 1 to clear this to 0. This bit will be set automatically, if the frequecy is lock and the RC_TRIM is enabled. Note: Reset by power on reset.
    0=The internal high-speed oscillator frequency doesn't lock at 48 MHz; 1=The internal high-speed oscillator frequency locked at 48 MHz
0x100 SYS_REGLCTL — Register Lock Control Register
  [7:0] REGLCTL — Register Lock Control Code. Some registers have write-protection function. Writing these registers have to disable the protected function by writing the sequence value '59h', '16h', '88h' to this field. After this sequence is completed, the REGLCTL bit will be set to 1 and write-protection registers can be normal write. . Register Lock Control Disable Index. The Protected registers are: NMIEN address 0x4000_0300. FMC_ISPCTL address 0x4000_C000 (Flash ISP Control register). FMC_ISPTRG address 0x4000_C010 (ISP Trigger Control register). FMC_ISPSTS address 0x4000_C040. WDT_CTL address 0x4004_0000. FMC_FTCTL address 0x4000_5018. FMC_ICPCMD address 0x4000_501C. EADC_TEST address 0x4004_3200. AHBMCTL address 0x4000_0400. SYS_IPRST0 address 0x4000_0008. SYS_BODCTL address 0x4000_0018. SYS_PORCTL0 address 0x4000_0024. SYS_SRAM_BISTCTL address 0x4000_00D0. SYS_PORCTL1 address 0x4000_1EC. CLK_PWRCTL address 0x4000_0200. CLK_APBCLK0[0] address 0x4000_0208. CLK_CLKSEL0 address 0x4000_0110. CLK_CLKSEL1[3:0] address 0x4000_0214. CLK_PLLCTL address 0x4000_0240. CLK_PMUCTL address 0x4000_0290. CLK_HXTFSEL address 0x4000_02B4. PWM_CTL0 address 0x4005_8000. PWM_CTL0 address 0x4005_9000. PWM_DTCTL0_1 address 0x4005_8070. PWM_DTCTL0_1 address 0x4005_9070. PWM_DTCTL2_3 address 0x4005_8074. PWM_DTCTL2_3 address 0x4005_9074. PWM_DTCTL4_5 address 0x4005_8078. PWM_DTCTL4_5 address 0x4005_9078. PWM_BRKCTL0_1 address 0x4005_80C8. PWM_BRKCTL0_1 address 0x4005_90C8. PWM_BRKCTL2_3 address 0x4005_80CC. PWM_BRKCTL2_3 address 0x4005_90CC. PWM_BRKCTL4_5 address 0x4005_80D0. PWM_BRKCTL4_5 address 0x4005_90D0. PWM_INTEN1 address 0x4005_80E4. PWM_INTEN1 address 0x4005_90E4. PWM_INTSTS1 address 0x4005_80EC. PWM_INTSTS1 address 0x4005_90EC. PWM_SELFTEST address 0x4005_8300. PWM_SELFTEST address 0x4005_930
    0=Write-protection Enabled for writing protected registers. Any write to the protected register is ignored; 1=Write-protection Disabled for writing protected registers
0x104 SYS_MIRCTRIMCTL reset 0x80010 — MIRC Trim Control Register
  [20:16] BOUNDARY — Boundary Selection. Fill the boundary range from 0x1 to 0x1F, 0x0 is reserved. Note: This field is effective only when the BOUNDEN(SYS_MIRCTRIMCTL[9]) is enabled
  [10] REFCKSEL — Reference Clock Selection
    0=MIRC trim reference clock is from LXT (32.768 kHz); 1=MIRC trim reference clock is from internal USB synchronous mode
  [9] BOUNDEN — Boundary Enable Bit
    0=Boundary function Disabled; 1=Boundary function Enabled
  [8] CESTOPEN — Clock Error Stop Enable Bit
    values as SYS_HIRCTRIMCTL.CESTOPEN
  [7:6] RETRYCNT — Trim Value Update Limitation Count. This field defines that how many times the auto trim circuit will try to update the MIRC trim value before the frequency of MIRC locked. Once the MIRC locked, the internal trim value update counter will be reset. If the trim value update counter reached this limitation value and frequency of MIRC still doesn't lock, the auto trim operation will be disabled and FREQSEL will be cleared to 00.
    values as SYS_HIRCTRIMCTL.RETRYCNT
  [5:4] LOOPSEL — Trim Calculation Loop Selection. This field defines that trim value calculation is based on how many reference clocks. Note: For example, if LOOPSEL is set as 00, auto trim circuit will calculate trim value based on the average frequency difference in 4 clocks of reference clock.
    1=Trim value calculation is based on average difference in 8 clocks of reference clock; 2=Trim value calculation is based on average difference in 16 clocks of reference clock; 3=Trim value calculation is based on average difference in 32 clocks of reference clock
  [1:0] FREQSEL — Trim Frequency Selection. This field indicates the target frequency of medium speed RC oscillator (MIRC) auto trim. During auto trim operation, if clock error detected with CESTOPEN is set to 1 or trim retry limitation count reached, this field will be cleared to 00 automatically.
    0=Disable HIRC auto trim function; 2=Enable HIRC auto trim function and trim MIRC to 4.032 MHz
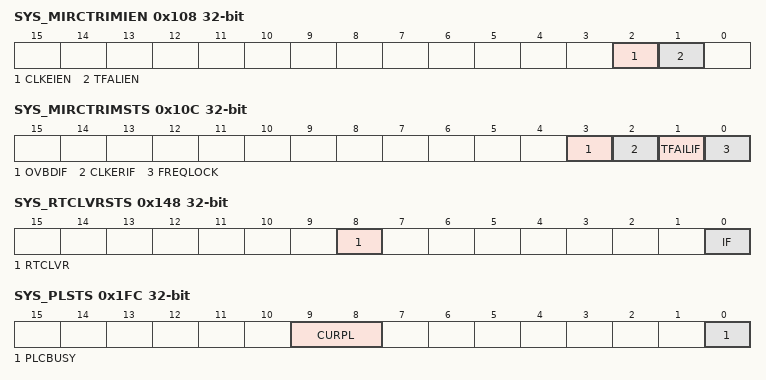
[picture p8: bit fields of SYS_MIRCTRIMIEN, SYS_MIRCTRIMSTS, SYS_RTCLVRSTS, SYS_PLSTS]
0x108 SYS_MIRCTRIMIEN — MIRC Trim Interrupt Enable Register
  [2] CLKEIEN — Clock Error Interrupt Enable Bit. This bit controls if CPU would get an interrupt while clock is inaccuracy during auto trim operation. If this bit is set to1, and CLKERRIF(SYS_MIRCTRIMSTS[2]) is set during auto trim operation, an interrupt will be triggered to notify the clock frequency is inaccuracy.
    0=Disable CLKERRIF(SYS_MIRCTRIMSTS[2]) status to trigger an interrupt to CPU; 1=Enable CLKERRIF(SYS_MIRCTRIMSTS[2]) status to trigger an interrupt to CPU
  [1] TFALIEN — Trim Failure Interrupt Enable Bit. This bit controls if an interrupt will be triggered while MIRC trim value update limitation count reached and MIRC frequency still not locked on target frequency set by FREQSEL(SYS_ MIRTRIMCTL[1:0]). If this bit is high and TFAILIF(SYS_ MIRCTRIMSTS[1]) is set during auto trim operation, an interrupt will be triggered to notify that MIRC trim value update limitation count was reached.
    0=Disable TFAILIF(SYS_MIRCTRIMSTS[1]) status to trigger an interrupt to CPU; 1=Enable TFAILIF(SYS_MIRCTRIMSTS[1]) status to trigger an interrupt to CPU
0x10C SYS_MIRCTRIMSTS — MIRC Trim Interrupt Status Register
  [3] OVBDIF — Over Boundary Status. When the over boundary function is set, if there occurs the over boundary condition, this flag will be set. Note: Write 1 to clear this flag.
    values as SYS_HIRCTRIMSTS.OVBDIF
  [2] CLKERIF — Clock Error Interrupt Status. When the frequency of 32.768 kHz external low speed crystal oscillator (LXT) or internal medium speed RC oscillator (MIRC) is shift larger to unreasonable value, this bit will be set and to be an indicate that clock frequency is inaccuracy. Once this bit is set to 1, the auto trim operation stopped and FREQSEL(SYS_MIRCTRIMCTL[1:0]) will be cleared to 00 by hardware automatically if CESTOPEN(SYS_MIRCTRIMCTL[8]) is set to 1. If this bit is set and CLKEIEN(SYS_MIRCTRIMIEN[2]) is high, an interrupt will be triggered to notify the clock frequency is inaccuracy. Write 1 to clear this to 0. Note: Reset by power on reset.
    values as SYS_HIRCTRIMSTS.CLKERIF
  [1] TFAILIF — Trim Failure Interrupt Status. This bit indicates that MIRC trim value update limitation count reached and the MIRC clock frequency still doesn't be locked. Once this bit is set, the auto trim operation stopped and FREQSEL(SYS_MIRCTRIMCTL[1:0]) will be cleared to 00 by hardware automatically. If this bit is set and TFAILIEN(SYS_MIRCTRIMIEN[1]) is high, an interrupt will be triggered to notify that MIRC trim value update limitation count was reached. Write 1 to clear this to 0. Note: Reset by power on reset.
    0=Trim value update limitation count does not reach; 1=Trim value update limitation count reached and MIRC frequency still not locked
  [0] FREQLOCK — MIRC Frequency Lock Status. This bit indicates the MIRC frequency is locked. This is a status bit and doesn't trigger any interrupt. Write 1 to clear this to 0. This bit will be set automatically, if the frequecy is lock and the RC_TRIM is enabled. Note: Reset by power on reset.
    0=The internal medium-speed oscillator frequency isn't locked; 1=The internal medium-speed oscillator frequency locked
0x144 SYS_RTCLVRIEN — RTC LVR Interrupt Control Register
  [0] IE — RTC LVR Interrupt Enable Bit (Write Protect)
    0=RTC LVR Interrupt Disabled (default); 1=RTC LVR Interrupt Enabled
0x148 SYS_RTCLVRSTS (reset mask 0xFFFFF0FF) — RTC LVR Interrupt Status Register
  [8] RTCLVR ro — RTCLVR value (read only)
  [0] IF — RTC LVR Interrupt Flag. When a positive edge of RTCLVR is detected, this bit will be set to 1 and will be cleared when a 1 is set to this bit. This bit is write protected
0x188 SYS_HIRCTCTL reset 0x10000 (reset mask 0xF0FF00FF) — HIRC Test Mode Control Register
0x1EC SYS_PORCTL1 — Power-On-reset Controller Register 1
  [15:0] POROFF — Power-on Reset Enable Bit (Write Protect). After powered on, User can turn off internal analog POR circuit to save power by writing 0x5AA5 to this field. The analog POR circuit will be active again when this field is set to another value or chip is reset by other reset source, including: nRESET, Watchdog, LVR reset, BOD reset, ICE reset command and the software-chip reset function. Note: This bit is write protected. Refer to the SYS_REGLCTL register.
0x1F8 SYS_PLCTL — Power Level Control Register
  [1:0] PLSEL — Power Level Select(Write Protect). Note : When at PL2, HCLK has to be lower than 4Mhz
    0=Set to power level 0 (PL0); 2=Set to power level 2 (PL2) [Internal note: this mode is MLDO low power mode]
0x1FC SYS_PLSTS (reset mask 0xFFFFFFF0) — Power Level Status Register
  [9:8] CURPL ro — Current Power Level (Read Only). This bit field reflect the current power level.
    0=Current power level is PL0; 2=Current power level is PL2. [Internal note: this mode is MLDO low power mode]
  [0] PLCBUSY ro — Power Level Change Busy Bit (Read Only). This bit is set by hardware when power level is changing. After power level change is completed, this bit will be cleared automatically by hardware.
    0=Power level change is completed; 1=Power level change is ongoing
